AUTOSAR XML (schema 4-1-3)
standard types defined: boolean, sint8, uint16, uint32, uint8, boolean_CompuMethod, boolean_DataConstr, sint8_DataConstr, uint16_DataConstr, uint32_DataConstr, uint8_DataConstr, sint16
package /MICROSAR/Dem_swc/DataTypes
  5 x impl type:
    Dem_DebounceResetStatusType: compu {0=DEM_DEBOUNCE_STATUS_FREEZE, 1=DEM_DEBOUNCE_STATUS_RESET}, range raw 0..255, implementation-data-type=ImplementationDataTypes/uint8
    Dem_DTCFormatType: compu {0=DEM_DTC_FORMAT_OBD, 1=DEM_DTC_FORMAT_UDS, 2=DEM_DTC_FORMAT_J1939}, range raw 0..2, implementation-data-type=ImplementationDataTypes/uint8
    Dem_EventStatusType:
      compu {0=DEM_EVENT_STATUS_PASSED, 1=DEM_EVENT_STATUS_FAILED, 2=DEM_EVENT_STATUS_PREPASSED, 3=DEM_EVENT_STATUS_PREFAILED, 4=DEM_EVENT_STATUS_FDC_THRESHOLD_REACHED, 5=DEM_EVENT_STATUS_PASSED_CONDITIONS_NOT_FULFILLED, 6=DEM_EVENT_STATUS_FAILED_CONDITIONS_NOT_FULFILLED, 7=DEM_EVENT_STATUS_PREPASSED_CONDITIONS_NOT_FULFILLED, 8=DEM_EVENT_STATUS_PREFAILED_CONDITIONS_NOT_FULFILLED}
      range raw 0..255
      implementation-data-type=ImplementationDataTypes/uint8
    Dem_MaxDataValueType: category=ARRAY, sw-calibration-access=READ-ONLY
      element Dem_MaxDataValueTypeElement: array-size=40, array-size-semantics=FIXED-SIZE, implementation-data-type=ImplementationDataTypes/uint8
    Dem_UdsStatusByteType:
      compu {mask 1: 1=DEM_UDS_STATUS_TF (bit 0: TestFailed), mask 2: 2=DEM_UDS_STATUS_TFTOC (bit 1: TestFailedThisOperationCycle), mask 4: 4=DEM_UDS_STATUS_PDTC (bit 2: PendingDTC), mask 8: 8=DEM_UDS_STATUS_CDTC (bit 3: ConfirmedDTC), mask 16: 16=DEM_UDS_STATUS_TNCSLC (bit 4: TestNotCompletedSinceLastClear), mask 32: 32=DEM_UDS_STATUS_TFSLC (bit 5: TestFailedSinceLastClear), mask 64: 64=DEM_UDS_STATUS_TNCTOC (bit 6: TestNotCompletedThisOperationCycle), mask 128: 128=DEM_UDS_STATUS_WIR (bit 7: WarningIndicatorRequested)}
      range raw 0..255
      implementation-data-type=ImplementationDataTypes/uint8
package /MICROSAR/Dem_swc/Interfaces
  client server interface DiagnosticMonitor: is-service=true, service-kind=DIAGNOSTIC-EVENT-MANAGER
    11 x operation:
      GetDTCOfEvent: possible-error=[DEM_E_NO_DTC_AVAILABLE, DiagnosticMonitor/E_NOT_OK]
        arg DTCFormat: type=Dem_DTCFormatType, direction=IN, server-argument-impl-policy=USE-ARGUMENT-TYPE
        arg DTCOfEvent: type=uint32, direction=OUT, server-argument-impl-policy=USE-ARGUMENT-TYPE
      GetEventExtendedDataRecordEx: possible-error=[DEM_BUFFER_TOO_SMALL, DEM_NO_SUCH_ELEMENT, DiagnosticMonitor/E_NOT_OK]
        arg RecordNumber: type=ImplementationDataTypes/uint8, direction=IN, server-argument-impl-policy=USE-ARGUMENT-TYPE
        arg DestBuffer: type=Dem_MaxDataValueType, direction=OUT, server-argument-impl-policy=USE-ARGUMENT-TYPE
        arg BufSize: type=ImplementationDataTypes/uint16, direction=INOUT, server-argument-impl-policy=USE-ARGUMENT-TYPE
      GetEventFailed: possible-error=DiagnosticMonitor/E_NOT_OK
        arg EventFailed: type=ImplementationDataTypes/boolean, direction=OUT, server-argument-impl-policy=USE-ARGUMENT-TYPE
      GetEventFreezeFrameDataEx: possible-error=[DEM_BUFFER_TOO_SMALL, DEM_NO_SUCH_ELEMENT, DiagnosticMonitor/E_NOT_OK]
        4 x arg, all with server-argument-impl-policy=USE-ARGUMENT-TYPE:
          RecordNumber: type=ImplementationDataTypes/uint8, direction=IN
          DataId: type=ImplementationDataTypes/uint16, direction=IN
          DestBuffer: type=Dem_MaxDataValueType, direction=OUT
          BufSize: type=ImplementationDataTypes/uint16, direction=INOUT
      GetEventStatus: possible-error=DiagnosticMonitor/E_NOT_OK
        arg UDSStatusByte: type=Dem_UdsStatusByteType, direction=OUT, server-argument-impl-policy=USE-ARGUMENT-TYPE
      GetEventTested: possible-error=DiagnosticMonitor/E_NOT_OK
        arg EventTested: type=ImplementationDataTypes/boolean, direction=OUT, server-argument-impl-policy=USE-ARGUMENT-TYPE
      GetEventUdsStatus: possible-error=DiagnosticMonitor/E_NOT_OK
        arg UDSStatusByte: type=Dem_UdsStatusByteType, direction=OUT, server-argument-impl-policy=USE-ARGUMENT-TYPE
      GetFaultDetectionCounter: possible-error=[DEM_E_NO_FDC_AVAILABLE, DiagnosticMonitor/E_NOT_OK]
        arg FaultDetectionCounter: type=sint8, direction=OUT, server-argument-impl-policy=USE-ARGUMENT-TYPE
      ResetEventDebounceStatus: possible-error=DiagnosticMonitor/E_NOT_OK
        arg DebounceResetStatus: type=Dem_DebounceResetStatusType, direction=IN, server-argument-impl-policy=USE-ARGUMENT-TYPE
      ResetEventStatus: possible-error=DiagnosticMonitor/E_NOT_OK
      SetEventStatus: possible-error=DiagnosticMonitor/E_NOT_OK
        arg EventStatus: type=Dem_EventStatusType, direction=IN, server-argument-impl-policy=USE-ARGUMENT-TYPE
    5 x error:
      DEM_BUFFER_TOO_SMALL: error-code=21
      DEM_E_NO_DTC_AVAILABLE: error-code=10
      DEM_E_NO_FDC_AVAILABLE: error-code=14
      DEM_NO_SUCH_ELEMENT: error-code=48
      E_NOT_OK: error-code=1
package /UAES/ASW/ApplicationDataTypes
  app type Fac_q0p001_u16: category=VALUE, sw-calibration-access=READ-WRITE, compu {phys=raw*0.001 for raw -INF..INF}, range phys 0..65.535
  app type U_q1_mV_u16: category=VALUE, sw-calibration-access=READ-WRITE, compu {phys=raw for raw -INF..INF; unit mV}, range raw 0..65535
package /UAES/ASW/CompuMethods
  compu method CM_boolean: 0=FALSE, 1=TRUE
package /UAES/ASW/DataConstrs
  range DC_boolean: raw 0..1
  range DC_sint16: raw -32768..32767
  range DC_uint16: phys 0..6553.5, raw 0..65535
  range DC_uint8: raw 0..255
package /UAES/ASW/DataTypeMappingSets
  data type mapping set DTMS_DcChrgrPileU3_DD
    data-type-maps:
      application-data-type=Fac_q0p001_u16, implementation-data-type=ImplementationDataTypes/uint16
      application-data-type=U_q1_mV_u16, implementation-data-type=ImplementationDataTypes/uint16
package /UAES/ASW/ImplementationDataTypes/Ground
  constant specification DcChrgrPileU3_uRawMaxSRC_C: value-spec=65535 mV
  constant specification DcChrgrPileU3_uRawMinSRC_C: value-spec=0 mV
package /UAES/ASW/PortInterfaces
  client server interface IoHwAb_IoSigAdc
    operation Adc_Get: possible-error=IoHwAb_IoSigAdc/E_NOT_OK
      arg id_u16: type=ImplementationDataTypes/uint16, direction=IN, server-argument-impl-policy=USE-ARGUMENT-TYPE
      arg val_s16: type=sint16, direction=OUT, server-argument-impl-policy=USE-ARGUMENT-TYPE
    operation AdcFac_Get: possible-error=IoHwAb_IoSigAdc/E_NOT_OK
      arg id_u16: type=ImplementationDataTypes/uint16, direction=IN, server-argument-impl-policy=USE-ARGUMENT-TYPE
      arg val_s16: type=sint16, direction=OUT, server-argument-impl-policy=USE-ARGUMENT-TYPE
    operation AdcVRMBatt_Get: possible-error=IoHwAb_IoSigAdc/E_NOT_OK
      arg id_u16: type=ImplementationDataTypes/uint16, direction=IN, server-argument-impl-policy=USE-ARGUMENT-TYPE
      arg val_u8: type=ImplementationDataTypes/uint8, direction=OUT, server-argument-impl-policy=USE-ARGUMENT-TYPE
    error E_NOT_OK: error-code=1
  10 x sender receiver interface:
    BattU_bVoltEnbPinDiag: invalidation-policy{data-element=BattU_bVoltEnbPinDiag/Val, handle-invalid=DONT-INVALIDATE}
      data Val: sw-calibration-access=READ-ONLY, type=ImplementationDataTypes/boolean
    BattU_VrmFac1: invalidation-policy{data-element=BattU_VrmFac1/Val, handle-invalid=DONT-INVALIDATE}
      data Val: sw-calibration-access=READ-ONLY, type=Fac_q0p001_u16
    BattU_VrmFac2: invalidation-policy{data-element=BattU_VrmFac2/Val, handle-invalid=DONT-INVALIDATE}
      data Val: sw-calibration-access=READ-ONLY, type=Fac_q0p001_u16
    BattU_VrmFac3: invalidation-policy{data-element=BattU_VrmFac3/Val, handle-invalid=DONT-INVALIDATE}
      data Val: sw-calibration-access=READ-ONLY, type=Fac_q0p001_u16
    DcChrgrPileU3_bVoltLvl: invalidation-policy{data-element=DcChrgrPileU3_bVoltLvl/Val, handle-invalid=DONT-INVALIDATE}
      data Val: sw-calibration-access=READ-ONLY, type=ImplementationDataTypes/boolean
    DcChrgrPileU3_flgSRCMaxErr: invalidation-policy{data-element=DcChrgrPileU3_flgSRCMaxErr/Val, handle-invalid=DONT-INVALIDATE}
      data Val: sw-calibration-access=READ-ONLY, type=ImplementationDataTypes/boolean
    DcChrgrPileU3_flgSRCMinErr: invalidation-policy{data-element=DcChrgrPileU3_flgSRCMinErr/Val, handle-invalid=DONT-INVALIDATE}
      data Val: sw-calibration-access=READ-ONLY, type=ImplementationDataTypes/boolean
    DcChrgrPileU3_uRaw: invalidation-policy{data-element=DcChrgrPileU3_uRaw/Val, handle-invalid=DONT-INVALIDATE}
      data Val: sw-calibration-access=READ-ONLY, type=U_q1_mV_u16
    gVRM_u16BatteryVolt_mv: invalidation-policy{data-element=gVRM_u16BatteryVolt_mv/Val, handle-invalid=DONT-INVALIDATE}
      data Val: sw-calibration-access=READ-ONLY, type=ImplementationDataTypes/uint16
    VehCoorn_stPwrMod: invalidation-policy{data-element=VehCoorn_stPwrMod/Val, handle-invalid=DONT-INVALIDATE}
      data Val: sw-calibration-access=READ-ONLY, type=ImplementationDataTypes/uint8
package /UAES/ASW/SwAddrMethods
  sw addr method CALDATA
package /UAES/ASW/SwComponentTypes
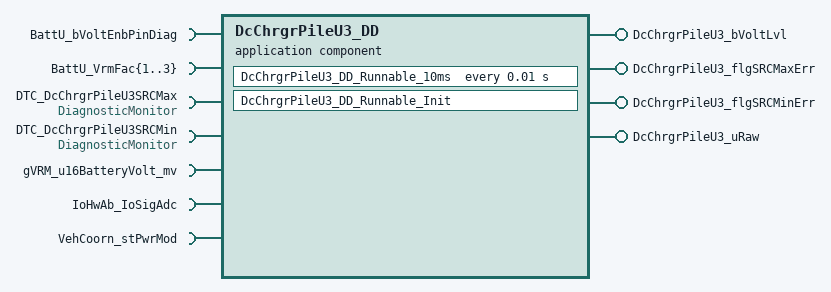
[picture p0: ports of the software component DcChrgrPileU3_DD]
  application sw component type DcChrgrPileU3_DD
    4 x provide port:
      DcChrgrPileU3_bVoltLvl: nonqueued-sender-com-spec{data-element=DcChrgrPileU3_bVoltLvl/Val, init-value=0}, provided-interface=DcChrgrPileU3_bVoltLvl
      DcChrgrPileU3_flgSRCMaxErr: nonqueued-sender-com-spec{data-element=DcChrgrPileU3_flgSRCMaxErr/Val, init-value=0}, provided-interface=DcChrgrPileU3_flgSRCMaxErr
      DcChrgrPileU3_flgSRCMinErr: nonqueued-sender-com-spec{data-element=DcChrgrPileU3_flgSRCMinErr/Val, init-value=0}, provided-interface=DcChrgrPileU3_flgSRCMinErr
      DcChrgrPileU3_uRaw: nonqueued-sender-com-spec{data-element=DcChrgrPileU3_uRaw/Val, init-value=0 mV}, provided-interface=DcChrgrPileU3_uRaw
    9 x require port:
      BattU_bVoltEnbPinDiag: nonqueued-receiver-com-spec{data-element=BattU_bVoltEnbPinDiag/Val, filter=data-filter-type=ALWAYS, init-value=0}, required-interface=BattU_bVoltEnbPinDiag
      BattU_VrmFac{1..3}: nonqueued-receiver-com-spec{data-element=BattU_VrmFac{1..3}/Val, filter=data-filter-type=ALWAYS, init-value=0}, required-interface=BattU_VrmFac{1..3}
      DTC_DcChrgrPileU3SRCMax: required-interface=DiagnosticMonitor
        required-com-specs:
          GetDTCOfEvent
          GetEventExtendedDataRecordEx
          GetEventFailed
          GetEventFreezeFrameDataEx
          GetEventStatus
          GetEventTested
          GetEventUdsStatus
          GetFaultDetectionCounter
          ResetEventDebounceStatus
          ResetEventStatus
          SetEventStatus
      DTC_DcChrgrPileU3SRCMin: required-interface=DiagnosticMonitor
        required-com-specs:
          GetDTCOfEvent
          GetEventExtendedDataRecordEx
          GetEventFailed
          GetEventFreezeFrameDataEx
          GetEventStatus
          GetEventTested
          GetEventUdsStatus
          GetFaultDetectionCounter
          ResetEventDebounceStatus
          ResetEventStatus
          SetEventStatus
      gVRM_u16BatteryVolt_mv: nonqueued-receiver-com-spec{data-element=gVRM_u16BatteryVolt_mv/Val, filter=data-filter-type=ALWAYS, init-value=0}, required-interface=gVRM_u16BatteryVolt_mv
      IoHwAb_IoSigAdc: required-com-specs=[Adc_Get, AdcFac_Get, AdcVRMBatt_Get], required-interface=IoHwAb_IoSigAdc
      VehCoorn_stPwrMod: nonqueued-receiver-com-spec{data-element=VehCoorn_stPwrMod/Val, filter=data-filter-type=ALWAYS, init-value=0}, required-interface=VehCoorn_stPwrMod
    behavior DcChrgrPileU3_DD_InternalBehavior: data-type-mapping=DTMS_DcChrgrPileU3_DD
      timing event TMT_DcChrgrPileU3_DD_Runnable_10ms: start-on-event=DcChrgrPileU3_DD_Runnable_10ms, period=0.01
      init event DcChrgrPileU3_DD_InitEvent: start-on-event=DcChrgrPileU3_DD_Runnable_Init
      runnable DcChrgrPileU3_DD_Runnable_10ms
        data-read-access:
          6 x access:
            READ_BattU_bVoltEnbPinDiag_Val: accessed-variable=BattU_bVoltEnbPinDiag.Val
            READ_BattU_VrmFac{1..3}_Val: accessed-variable=BattU_VrmFac{1..3}.Val
            READ_gVRM_u16BatteryVolt_mv_Val: accessed-variable=gVRM_u16BatteryVolt_mv.Val
            READ_VehCoorn_stPwrMod_Val: accessed-variable=VehCoorn_stPwrMod.Val
        data-write-access:
          4 x access:
            OUT_DcChrgrPileU3_flgSRCMaxErr_Val: accessed-variable=DcChrgrPileU3_flgSRCMaxErr.Val
            OUT_DcChrgrPileU3_flgSRCMinErr_Val: accessed-variable=DcChrgrPileU3_flgSRCMinErr.Val
            OUT_DcChrgrPileU3_uRaw_Val: accessed-variable=DcChrgrPileU3_uRaw.Val
            WRITE_DcChrgrPileU3_bVoltLvl_Val: accessed-variable=DcChrgrPileU3_bVoltLvl.Val
        parameter access PA_DcChrgrPileU3_uRawMaxSRC_C: accessed-parameter=DcChrgrPileU3_uRawMaxSRC_C
        parameter access PA_DcChrgrPileU3_uRawMinSRC_C: accessed-parameter=DcChrgrPileU3_uRawMinSRC_C
        9 x sync call:
          SC_DTC_DcChrgrPileU3SRCMax_GetEventFailed: operation=DTC_DcChrgrPileU3SRCMax.GetEventFailed, timeout=1E-06
          SC_DTC_DcChrgrPileU3SRCMax_GetEventTested: operation=DTC_DcChrgrPileU3SRCMax.GetEventTested, timeout=1E-06
          SC_DTC_DcChrgrPileU3SRCMax_ResetEventDebounceStatus: operation=DTC_DcChrgrPileU3SRCMax.ResetEventDebounceStatus, timeout=1E-06
          SC_DTC_DcChrgrPileU3SRCMax_SetEventStatus: operation=DTC_DcChrgrPileU3SRCMax.SetEventStatus, timeout=1E-06
          SC_DTC_DcChrgrPileU3SRCMin_GetEventFailed: operation=DTC_DcChrgrPileU3SRCMin.GetEventFailed, timeout=1E-06
          SC_DTC_DcChrgrPileU3SRCMin_GetEventTested: operation=DTC_DcChrgrPileU3SRCMin.GetEventTested, timeout=1E-06
          SC_DTC_DcChrgrPileU3SRCMin_ResetEventDebounceStatus: operation=DTC_DcChrgrPileU3SRCMin.ResetEventDebounceStatus, timeout=1E-06
          SC_DTC_DcChrgrPileU3SRCMin_SetEventStatus: operation=DTC_DcChrgrPileU3SRCMin.SetEventStatus, timeout=1E-06
          SC_IoHwAb_AdcFac_Get_AdcFac_Get: operation=IoHwAb_IoSigAdc.AdcFac_Get, timeout=0
      runnable DcChrgrPileU3_DD_Runnable_Init
        data-read-access:
          4 x access:
            READ_BattU_VrmFac{1..3}_Val: accessed-variable=BattU_VrmFac{1..3}.Val
            READ_gVRM_u16BatteryVolt_mv_Val: accessed-variable=gVRM_u16BatteryVolt_mv.Val
        data-write-access:
          4 x access:
            OUT_DcChrgrPileU3_uRaw_Val: accessed-variable=DcChrgrPileU3_uRaw.Val
            WRITE_DcChrgrPileU3_bVoltLvl_Val: accessed-variable=DcChrgrPileU3_bVoltLvl.Val
            WRITE_DcChrgrPileU3_flgSRCMaxErr_Val: accessed-variable=DcChrgrPileU3_flgSRCMaxErr.Val
            WRITE_DcChrgrPileU3_flgSRCMinErr_Val: accessed-variable=DcChrgrPileU3_flgSRCMinErr.Val
        parameter access PA_DcChrgrPileU3_uRawMaxSRC_C: accessed-parameter=DcChrgrPileU3_uRawMaxSRC_C
        parameter access PA_DcChrgrPileU3_uRawMinSRC_C: accessed-parameter=DcChrgrPileU3_uRawMinSRC_C
        sync call SC_IoHwAb_AdcFac_Get_AdcFac_Get: operation=IoHwAb_IoSigAdc.AdcFac_Get, timeout=0
      shared-parameters:
        parameter data prototype DcChrgrPileU3_uRawMaxSRC_C: sw-addr-method=CALDATA, sw-calibration-access=READ-WRITE, type=U_q1_mV_u16, init-value=constant-reference={short-label=DcChrgrPileU3_uRawMaxSRC_C, constant=DcChrgrPileU3_uRawMaxSRC_C}
        parameter data prototype DcChrgrPileU3_uRawMinSRC_C: sw-addr-method=CALDATA, sw-calibration-access=READ-WRITE, type=U_q1_mV_u16, init-value=constant-reference={short-label=DcChrgrPileU3_uRawMinSRC_C, constant=DcChrgrPileU3_uRawMinSRC_C}
  swc implementation DcChrgrPileU3_DD_imp: behavior=DcChrgrPileU3_DD_InternalBehavior
    code-descriptors:
      code Default: artifact-descriptors=autosar-engineering-object={short-label=Default, category=SWSRC}
package /UAES/ASW/Units
  unit mV: display-name=mV, factor-si-to-unit=1, offset-si-to-unit=0
  unit NoUnit: factor-si-to-unit=1, offset-si-to-unit=0
package /UAES/DataConstrs
  range DC_UInt16: raw 0..65535
